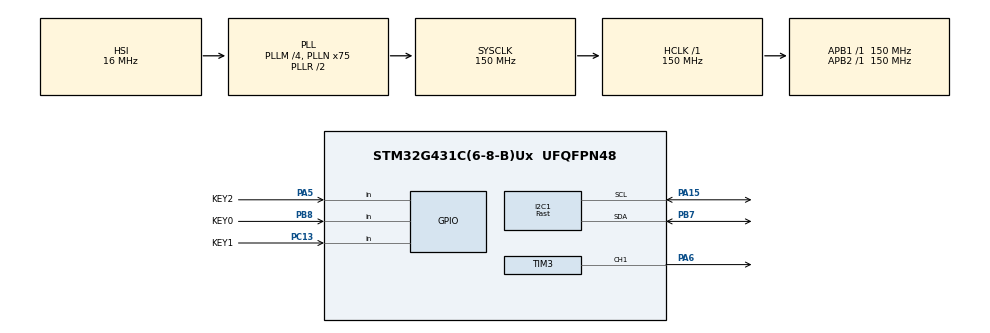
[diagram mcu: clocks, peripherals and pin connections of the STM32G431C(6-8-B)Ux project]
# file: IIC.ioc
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Dma.Request0=TIM3_CH1
Dma.TIM3_CH1.0.Direction=DMA_MEMORY_TO_PERIPH
Dma.TIM3_CH1.0.EventEnable=DISABLE
Dma.TIM3_CH1.0.Instance=DMA1_Channel1
Dma.TIM3_CH1.0.MemDataAlignment=DMA_MDATAALIGN_HALFWORD
Dma.TIM3_CH1.0.MemInc=DMA_MINC_ENABLE
Dma.TIM3_CH1.0.Mode=DMA_NORMAL
Dma.TIM3_CH1.0.PeriphDataAlignment=DMA_PDATAALIGN_HALFWORD
Dma.TIM3_CH1.0.PeriphInc=DMA_PINC_DISABLE
Dma.TIM3_CH1.0.Polarity=HAL_DMAMUX_REQ_GEN_RISING
Dma.TIM3_CH1.0.Priority=DMA_PRIORITY_MEDIUM
Dma.TIM3_CH1.0.RequestNumber=1
Dma.TIM3_CH1.0.SignalID=NONE
Dma.TIM3_CH1.0.SyncEnable=DISABLE
Dma.TIM3_CH1.0.SyncPolarity=HAL_DMAMUX_SYNC_NO_EVENT
Dma.TIM3_CH1.0.SyncRequestNumber=1
Dma.TIM3_CH1.0.SyncSignalID=NONE
I2C1.Analog_Filter=I2C_ANALOGFILTER_DISABLE
I2C1.I2C_Speed_Mode=I2C_Fast
I2C1.NoStretchMode=I2C_NOSTRETCH_DISABLE
I2C1.Timing=0x00E072FF
Mcu.Family=STM32G4
Mcu.Name=STM32G431C(6-8-B)Ux
Mcu.Package=UFQFPN48
NVIC.DMA1_Channel1_IRQn=true\:0\:0\:false\:false\:true\:false\:true\:true
NVIC.PriorityGroup=NVIC_PRIORITYGROUP_2
NVIC.TIM6_DAC_IRQn=true\:2\:2\:true\:false\:true\:true\:true\:true
PA13.Mode=Serial_Wire
PA13.Signal=SYS_JTMS-SWDIO
PA14.Mode=Serial_Wire
PA14.Signal=SYS_JTCK-SWCLK
PA15.Mode=I2C
PA15.Signal=I2C1_SCL
PA5.GPIO_Label=KEY2
PA5.GPIO_PuPd=GPIO_PULLUP
PA5.Signal=GPIO_Input
PA6.Signal=S_TIM3_CH1
PB7.Mode=I2C
PB7.Signal=I2C1_SDA
PB8-BOOT0.GPIO_Label=KEY0
PB8-BOOT0.GPIO_PuPd=GPIO_PULLUP
PB8-BOOT0.Signal=GPIO_Input
PC13.GPIO_Label=KEY1
PC13.GPIO_PuPd=GPIO_PULLUP
PC13.Signal=GPIO_Input
PF0-OSC_IN.Mode=HSE-External-Oscillator
PF0-OSC_IN.Signal=RCC_OSC_IN
PF1-OSC_OUT.Mode=HSE-External-Oscillator
PF1-OSC_OUT.Signal=RCC_OSC_OUT
ProjectManager.HeapSize=0x200
ProjectManager.StackSize=0x400
ProjectManager.TargetToolchain=MDK-ARM V5.32
RCC.ADC12Freq_Value=150000000
RCC.AHBFreq_Value=150000000
RCC.APB1Freq_Value=150000000
RCC.APB1TimFreq_Value=150000000
RCC.APB2Freq_Value=150000000
RCC.APB2TimFreq_Value=150000000
RCC.CortexFreq_Value=150000000
RCC.EXTERNAL_CLOCK_VALUE=12288000
RCC.HCLKFreq_Value=150000000
RCC.HSE_VALUE=8000000
RCC.HSI48_VALUE=48000000
RCC.HSI_VALUE=16000000
RCC.LSE_VALUE=32768
RCC.PLLM=RCC_PLLM_DIV4
RCC.PLLN=75
RCC.SYSCLKFreq_VALUE=150000000
RCC.SYSCLKSource=RCC_SYSCLKSOURCE_PLLCLK
RCC.USBFreq_Value=150000000
RCC.VCOOutputFreq_Value=300000000
SH.S_TIM3_CH1.0=TIM3_CH1,PWM Generation1 CH1
TIM3.Channel-PWM\ Generation1\ CH1=TIM_CHANNEL_1
TIM3.PeriodNoDither=188 - 1
TIM3.Prescaler=1 - 1
TIM6.AutoReloadPreload=TIM_AUTORELOAD_PRELOAD_ENABLE
TIM6.PeriodNoDither=1000 - 1
TIM6.Prescaler=150 - 1
VP_SYS_VS_DBSignals.Mode=DisableDeadBatterySignals
VP_TIM3_VS_ClockSourceINT.Mode=Internal
VP_TIM6_VS_ClockSourceINT.Mode=Enable_Timer
board=custom

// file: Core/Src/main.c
/* USER CODE BEGIN Header */
/**
  ******************************************************************************
  * @file           : main.c
  * @brief          : Main program body
  ******************************************************************************
  * @attention
  *
  * Copyright (c) 2025 STMicroelectronics.
  * All rights reserved.
  *
  * This software is licensed under terms that can be found in the LICENSE file
  * in the root directory of this software component.
  * If no LICENSE file comes with this software, it is provided AS-IS.
  *
  ******************************************************************************
  */
/* USER CODE END Header */
#include "main.h"
#include "dma.h"
#include "i2c.h"
#include "tim.h"
#include "gpio.h"

/* USER CODE BEGIN Includes */
#include "../../BSP/OLED/oled.h"
#include "../../BSP/WS2812B/WS2812B.h"
/* USER CODE END Includes */

void SystemClock_Config(void);

/* USER CODE BEGIN 0 */
uint8_t WhiteLight_Brightness;
uint8_t UpdateFlag=1;
/* USER CODE END 0 */

int main(void)
{

  /* USER CODE BEGIN 1 */
/**************************************************************
 *                          _ooOoo_
 *                         o8888888o
 *                         88" . "88
 *                         (| -_- |)
 *                         O\  =  /O
 *                      ____/`---'\____
 *                    .'  \\|     |//  `.
 *                   /  \\|||  :  |||//  \
 *                  /  _||||| -:- |||||-  \
 *                  |   | \\\  -  /// |   |
 *                  | \_|  ''\---/''  |   |
 *                  \  .-\__  `-`  ___/-. /
 *                ___`. .'  /--.--\  `. . __
 *             ."" '<  `.___\_<|>_/___.'  >'"".
 *            | | :  `- \`.;`\ _ /`;.`/ - ` : | |
 *            \  \ `-.   \_ __\ /__ _/   .-` /  /
 *       ======`-.____`-.___\_____/___.-`____.-'======
 *                          `=---='
 *
 *       ^^^^^^^^^^^^^^^^^^^^^^^^^^^^^^^^^^^^^^^^^^^^^
 *                佛祖保佑       永无BUG
 **************************************************************/

  /* USER CODE END 1 */

  /* MCU Configuration--------------------------------------------------------*/

  /* Reset of all peripherals, Initializes the Flash interface and the Systick. */
  HAL_Init();

  /* Configure the system clock */
  SystemClock_Config();

  /* Initialize all configured peripherals */
  MX_GPIO_Init();
  MX_DMA_Init();
  MX_I2C1_Init();
  MX_TIM6_Init();
  MX_TIM3_Init();
  /* USER CODE BEGIN 2 */
	OLED_Init();
  /* USER CODE END 2 */

  /* Infinite loop */
  while (1)
  {

    /* USER CODE BEGIN 3 */

//    WS2812B_SetBuf(0x000000);
//    WS2812B_UpdateBuf();

	ColorRGB(1000);
  }
  /* USER CODE END 3 */
}

void SystemClock_Config(void)
{
  RCC_OscInitTypeDef RCC_OscInitStruct = {0};
  RCC_ClkInitTypeDef RCC_ClkInitStruct = {0};

  /** Configure the main internal regulator output voltage
  */
  HAL_PWREx_ControlVoltageScaling(PWR_REGULATOR_VOLTAGE_SCALE1);

  /** Initializes the RCC Oscillators according to the specified parameters
  * in the RCC_OscInitTypeDef structure.
  */
  RCC_OscInitStruct.OscillatorType = RCC_OSCILLATORTYPE_HSI;
  RCC_OscInitStruct.HSIState = RCC_HSI_ON;
  RCC_OscInitStruct.HSICalibrationValue = RCC_HSICALIBRATION_DEFAULT;
  RCC_OscInitStruct.PLL.PLLState = RCC_PLL_ON;
  RCC_OscInitStruct.PLL.PLLSource = RCC_PLLSOURCE_HSI;
  RCC_OscInitStruct.PLL.PLLM = RCC_PLLM_DIV4;
  RCC_OscInitStruct.PLL.PLLN = 75;
  RCC_OscInitStruct.PLL.PLLP = RCC_PLLP_DIV2;
  RCC_OscInitStruct.PLL.PLLQ = RCC_PLLQ_DIV2;
  RCC_OscInitStruct.PLL.PLLR = RCC_PLLR_DIV2;
  if (HAL_RCC_OscConfig(&RCC_OscInitStruct) != HAL_OK)
  {
    Error_Handler();
  }

  /** Initializes the CPU, AHB and APB buses clocks
  */
  RCC_ClkInitStruct.ClockType = RCC_CLOCKTYPE_HCLK|RCC_CLOCKTYPE_SYSCLK
                              |RCC_CLOCKTYPE_PCLK1|RCC_CLOCKTYPE_PCLK2;
  RCC_ClkInitStruct.SYSCLKSource = RCC_SYSCLKSOURCE_PLLCLK;
  RCC_ClkInitStruct.AHBCLKDivider = RCC_SYSCLK_DIV1;
  RCC_ClkInitStruct.APB1CLKDivider = RCC_HCLK_DIV1;
  RCC_ClkInitStruct.APB2CLKDivider = RCC_HCLK_DIV1;

  if (HAL_RCC_ClockConfig(&RCC_ClkInitStruct, FLASH_LATENCY_4) != HAL_OK)
  {
    Error_Handler();
  }
}

void Error_Handler(void)
{
  __disable_irq();
  while (1)
  {
  }
}
